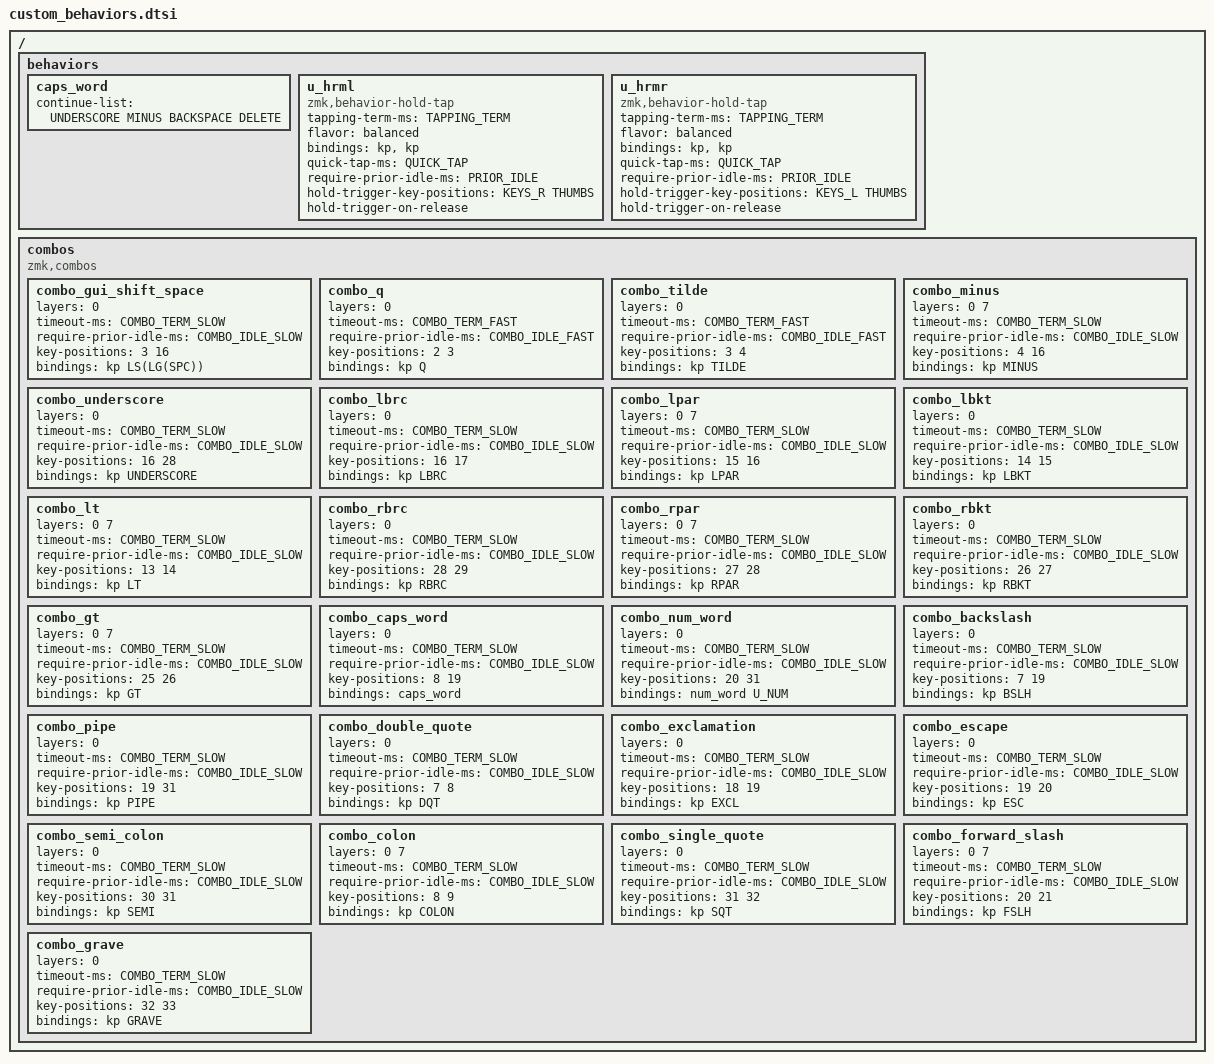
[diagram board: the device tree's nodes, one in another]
#include <behaviors/num_word.dtsi>

/*                                      42 KEY MATRIX / LAYOUT MAPPING

  ╭────────────────────────┬────────────────────────╮
  │  0   1   2   3   4   5 │  6   7   8   9  10  11 │
  │ 12  13  14  15  16  17 │ 18  19  20  21  22  23 │
  │ 24  25  26  27  28  29 │ 30  31  32  33  34  35 │
  ╰───────────╮ 36  37  38 │ 39  40  41 ╭───────────╯
              ╰────────────┴────────────╯               */

#define KEYS_L 0 1 2 3 4 5 12 13 14 15 16 17 24 25 26 27 28 29
#define KEYS_R 6 7 8 9 10 11 18 19 20 21 22 23 30 31 32 33 34 35
#define THUMBS 36 37 38 39 40 41

#define COMBO_TERM_FAST 30
#define COMBO_TERM_SLOW 40

#define COMBO_IDLE_FAST 150
#define COMBO_IDLE_SLOW 50

#define TAPPING_TERM 280
#define QUICK_TAP 175
#define PRIOR_IDLE 50

/ {
  behaviors {
    /* Let Caps Word continue when typing Underscore */
    caps_word {
        continue-list = <UNDERSCORE MINUS BACKSPACE DELETE>;
    };
    u_hrml: u_hrml {
      compatible = "zmk,behavior-hold-tap";
      #binding-cells = <2>;
      tapping-term-ms = <TAPPING_TERM>;
      flavor = "balanced";
      bindings = <&kp>, <&kp>;
      quick-tap-ms = <QUICK_TAP>;                // repeat on tap-into-hold
      require-prior-idle-ms = <PRIOR_IDLE>;
      hold-trigger-key-positions = <KEYS_R THUMBS>;
      hold-trigger-on-release;             // delay positional check until key-release
    };
    u_hrmr: u_hrmr {
      compatible = "zmk,behavior-hold-tap";
      #binding-cells = <2>;
      tapping-term-ms = <TAPPING_TERM>;
      flavor = "balanced";
      bindings = <&kp>, <&kp>;
      quick-tap-ms = <QUICK_TAP>;                // repeat on tap-into-hold
      require-prior-idle-ms = <PRIOR_IDLE>;
      hold-trigger-key-positions = <KEYS_L THUMBS>;
      hold-trigger-on-release;             // delay positional check until key-release
    };
  };
};

/*                                      42 KEY MATRIX / LAYOUT MAPPING

  ╭────────────────────────┬────────────────────────╮
  │  0   1   2   3   4   5 │  6   7   8   9  10  11 │
  │ 12  13  14  15  16  17 │ 18  19  20  21  22  23 │
  │ 24  25  26  27  28  29 │ 30  31  32  33  34  35 │
  ╰───────────╮ 36  37  38 │ 39  40  41 ╭───────────╯
              ╰────────────┴────────────╯               */

/ {
    combos {
        // Combo for left parenthesis key
        compatible = "zmk,combos";

        // LEFT
        combo_gui_shift_space {
            layers = <0>;
            timeout-ms = <COMBO_TERM_SLOW>;
            require-prior-idle-ms = <COMBO_IDLE_SLOW>;
            key-positions = <3 16>;
            bindings = <&kp LS(LG(SPC))>;
        };
        combo_q {
            layers = <0>;
            timeout-ms = <COMBO_TERM_FAST>;
            require-prior-idle-ms = <COMBO_IDLE_FAST>;
            key-positions = <2 3>;
            bindings = <&kp Q>;
        };
        combo_tilde {
            layers = <0>;
            timeout-ms = <COMBO_TERM_FAST>;
            require-prior-idle-ms = <COMBO_IDLE_FAST>;
            key-positions = <3 4>;
            bindings = <&kp TILDE>;
        };
        combo_minus {
            layers = <0 7>;
            timeout-ms = <COMBO_TERM_SLOW>;
            require-prior-idle-ms = <COMBO_IDLE_SLOW>;
            key-positions = <4 16>;
            bindings = <&kp MINUS>;
        };
        combo_underscore {
            layers = <0>;
            timeout-ms = <COMBO_TERM_SLOW>;
            require-prior-idle-ms = <COMBO_IDLE_SLOW>;
            key-positions = <16 28>;
            bindings = <&kp UNDERSCORE>;
        };
        combo_lbrc {
            layers = <0>;
            timeout-ms = <COMBO_TERM_SLOW>;
            require-prior-idle-ms = <COMBO_IDLE_SLOW>;
            key-positions = <16 17>;
            bindings = <&kp LBRC>;
        };
        combo_lpar {
            layers = <0 7>;
            timeout-ms = <COMBO_TERM_SLOW>;
            require-prior-idle-ms = <COMBO_IDLE_SLOW>;
            key-positions = <15 16>;
            bindings = <&kp LPAR>;
        };
        combo_lbkt {
            layers = <0>;
            timeout-ms = <COMBO_TERM_SLOW>;
            require-prior-idle-ms = <COMBO_IDLE_SLOW>;
            key-positions = <14 15>;
            bindings = <&kp LBKT>;
        };
        combo_lt {
            layers = <0 7>;
            timeout-ms = <COMBO_TERM_SLOW>;
            require-prior-idle-ms = <COMBO_IDLE_SLOW>;
            key-positions = <13 14>;
            bindings = <&kp LT>;
        };
        combo_rbrc {
            layers = <0>;
            timeout-ms = <COMBO_TERM_SLOW>;
            require-prior-idle-ms = <COMBO_IDLE_SLOW>;
            key-positions = <28 29>;
            bindings = <&kp RBRC>;
        };
        combo_rpar {
            layers = <0 7>;
            timeout-ms = <COMBO_TERM_SLOW>;
            require-prior-idle-ms = <COMBO_IDLE_SLOW>;
            key-positions = <27 28>;
            bindings = <&kp RPAR>;
        };
        combo_rbkt {
            layers = <0>;
            timeout-ms = <COMBO_TERM_SLOW>;
            require-prior-idle-ms = <COMBO_IDLE_SLOW>;
            key-positions = <26 27>;
            bindings = <&kp RBKT>;
        };
        combo_gt {
            layers = <0 7>;
            timeout-ms = <COMBO_TERM_SLOW>;
            require-prior-idle-ms = <COMBO_IDLE_SLOW>;
            key-positions = <25 26>;
            bindings = <&kp GT>;
        };

        // RIGHT 
        combo_caps_word {
            layers = <0>;
            timeout-ms = <COMBO_TERM_SLOW>;
            require-prior-idle-ms = <COMBO_IDLE_SLOW>;
            key-positions = <8 19>;
            bindings = <&caps_word>;
        };
        combo_num_word {
            layers = <0>;
            timeout-ms = <COMBO_TERM_SLOW>;
            require-prior-idle-ms = <COMBO_IDLE_SLOW>;
            key-positions = <20 31>;
            bindings = <&num_word U_NUM>;
        };
        combo_backslash {
            layers = <0>;
            timeout-ms = <COMBO_TERM_SLOW>;
            require-prior-idle-ms = <COMBO_IDLE_SLOW>;
            key-positions = <7 19>;
            bindings = <&kp BSLH>;
        };
        combo_pipe {
            layers = <0>;
            timeout-ms = <COMBO_TERM_SLOW>;
            require-prior-idle-ms = <COMBO_IDLE_SLOW>;
            key-positions = <19 31>;
            bindings = <&kp PIPE>;
        };
        combo_double_quote {
            layers = <0>;
            timeout-ms = <COMBO_TERM_SLOW>;
            require-prior-idle-ms = <COMBO_IDLE_SLOW>;
            key-positions = <7 8>;
            bindings = <&kp DQT>;
        };
        combo_exclamation {
            layers = <0>;
            timeout-ms = <COMBO_TERM_SLOW>;
            require-prior-idle-ms = <COMBO_IDLE_SLOW>;
            key-positions = <18 19>;
            bindings = <&kp EXCL>;
        };
        combo_escape {
            layers = <0>;
            timeout-ms = <COMBO_TERM_SLOW>;
            require-prior-idle-ms = <COMBO_IDLE_SLOW>;
            key-positions = <19 20>;
            bindings = <&kp ESC>;
        };
        combo_semi_colon {
            layers = <0>;
            timeout-ms = <COMBO_TERM_SLOW>;
            require-prior-idle-ms = <COMBO_IDLE_SLOW>;
            key-positions = <30 31>;
            bindings = <&kp SEMI>;
        };
        combo_colon {
            layers = <0 7>;
            timeout-ms = <COMBO_TERM_SLOW>;
            require-prior-idle-ms = <COMBO_IDLE_SLOW>;
            key-positions = <8 9>;
            bindings = <&kp COLON>;
        };
        combo_single_quote {
            layers = <0>;
            timeout-ms = <COMBO_TERM_SLOW>;
            require-prior-idle-ms = <COMBO_IDLE_SLOW>;
            key-positions = <31 32>;
            bindings = <&kp SQT>;
        };
        combo_forward_slash {
            layers = <0 7>;
            timeout-ms = <COMBO_TERM_SLOW>;
            require-prior-idle-ms = <COMBO_IDLE_SLOW>;
            key-positions = <20 21>;
            bindings = <&kp FSLH>;
        };
        combo_grave {
            layers = <0>;
            timeout-ms = <COMBO_TERM_SLOW>;
            require-prior-idle-ms = <COMBO_IDLE_SLOW>;
            key-positions = <32 33>;
            bindings = <&kp GRAVE>;
        };
    };
};

